AUTOSAR XML (schema 4-0-3)
package /CHMR_Code_pkg/CHMR_Code_swc
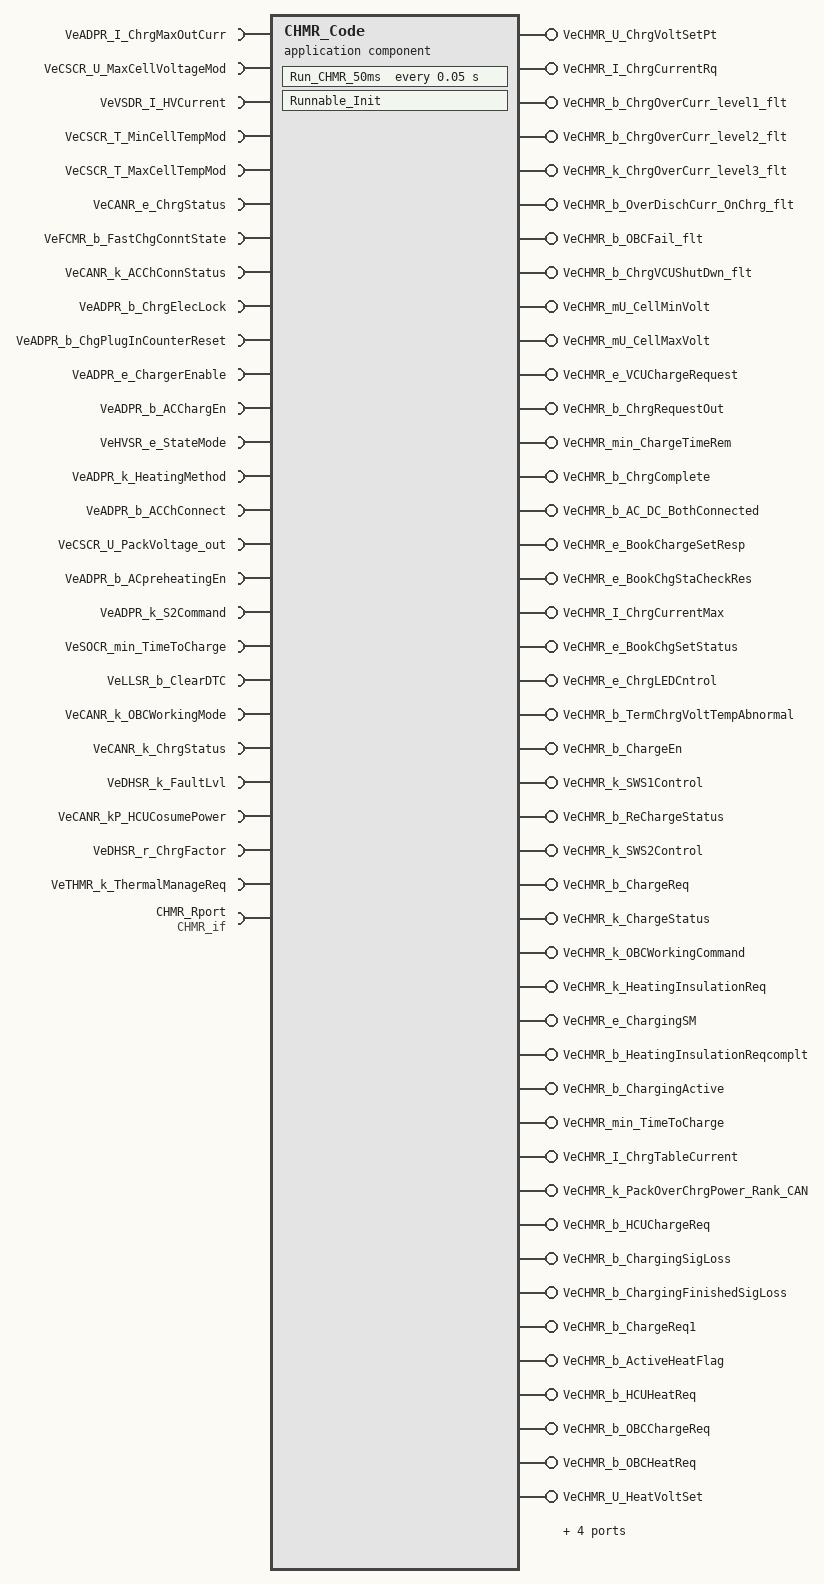
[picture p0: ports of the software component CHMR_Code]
  application sw component type CHMR_Code
    26 x require port:
      VeADPR_I_ChrgMaxOutCurr: nonqueued-receiver-com-spec{data-element=VeADPR_I_ChrgMaxOutCurr, init-value=0}, required-interface=VeADPR_I_ChrgMaxOutCurr
      VeCSCR_U_MaxCellVoltageMod: nonqueued-receiver-com-spec{data-element=VeCSCR_U_MaxCellVoltageMod, init-value=0}, required-interface=VeCSCR_U_MaxCellVoltageMod
      VeVSDR_I_HVCurrent: nonqueued-receiver-com-spec{data-element=VeVSDR_I_HVCurrent, init-value=0}, required-interface=VeVSDR_I_HVCurrent
      VeCSCR_T_MinCellTempMod: nonqueued-receiver-com-spec{data-element=VeCSCR_T_MinCellTempMod, init-value=0}, required-interface=VeCSCR_T_MinCellTempMod
      VeCSCR_T_MaxCellTempMod: nonqueued-receiver-com-spec{data-element=VeCSCR_T_MaxCellTempMod, init-value=0}, required-interface=VeCSCR_T_MaxCellTempMod
      VeCANR_e_ChrgStatus: nonqueued-receiver-com-spec{data-element=VeCANR_e_ChrgStatus, init-value=CeCHMR_e_ChrgModeReserved1}, required-interface=VeCANR_e_ChrgStatus
      VeFCMR_b_FastChgConntState: nonqueued-receiver-com-spec{data-element=VeFCMR_b_FastChgConntState, init-value=0}, required-interface=VeFCMR_b_FastChgConntState
      VeCANR_k_ACChConnStatus: nonqueued-receiver-com-spec{data-element=VeCANR_k_ACChConnStatus, init-value=0}, required-interface=VeCANR_k_ACChConnStatus
      VeADPR_b_ChrgElecLock: nonqueued-receiver-com-spec{data-element=VeADPR_b_ChrgElecLock, init-value=0}, required-interface=VeADPR_b_ChrgElecLock
      VeADPR_b_ChgPlugInCounterReset: nonqueued-receiver-com-spec{data-element=VeADPR_b_ChgPlugInCounterReset, init-value=0}, required-interface=VeADPR_b_ChgPlugInCounterReset
      VeADPR_e_ChargerEnable: nonqueued-receiver-com-spec{data-element=VeADPR_e_ChargerEnable, init-value=CeCHMR_e_OBC_ChrgEnblDefault}, required-interface=VeADPR_e_ChargerEnable
      VeADPR_b_ACChargEn: nonqueued-receiver-com-spec{data-element=VeADPR_b_ACChargEn, init-value=0}, required-interface=VeADPR_b_ACChargEn
      VeHVSR_e_StateMode: nonqueued-receiver-com-spec{data-element=VeHVSR_e_StateMode, init-value=CeHVSR_e_StateModeReserved}, required-interface=VeHVSR_e_StateMode
      VeADPR_k_HeatingMethod: nonqueued-receiver-com-spec{data-element=VeADPR_k_HeatingMethod, init-value=0}, required-interface=VeADPR_k_HeatingMethod
      VeADPR_b_ACChConnect: nonqueued-receiver-com-spec{data-element=VeADPR_b_ACChConnect, init-value=0}, required-interface=VeADPR_b_ACChConnect
      VeCSCR_U_PackVoltage_out: nonqueued-receiver-com-spec{data-element=VeCSCR_U_PackVoltage_out, init-value=0}, required-interface=VeCSCR_U_PackVoltage_out
      VeADPR_b_ACpreheatingEn: nonqueued-receiver-com-spec{data-element=VeADPR_b_ACpreheatingEn, init-value=0}, required-interface=VeADPR_b_ACpreheatingEn
      VeADPR_k_S2Command: nonqueued-receiver-com-spec{data-element=VeADPR_k_S2Command, init-value=0}, required-interface=VeADPR_k_S2Command
      VeSOCR_min_TimeToCharge: nonqueued-receiver-com-spec{data-element=VeSOCR_min_TimeToCharge, init-value=0}, required-interface=VeSOCR_min_TimeToCharge
      VeLLSR_b_ClearDTC: nonqueued-receiver-com-spec{data-element=VeLLSR_b_ClearDTC, init-value=0}, required-interface=VeLLSR_b_ClearDTC
      VeCANR_k_OBCWorkingMode: nonqueued-receiver-com-spec{data-element=VeCANR_k_OBCWorkingMode, init-value=0}, required-interface=VeCANR_k_OBCWorkingMode
      VeCANR_k_ChrgStatus: nonqueued-receiver-com-spec{data-element=VeCANR_k_ChrgStatus, init-value=0}, required-interface=VeCANR_k_ChrgStatus
      VeDHSR_k_FaultLvl: nonqueued-receiver-com-spec{data-element=VeDHSR_k_FaultLvl, init-value=0}, required-interface=VeDHSR_k_FaultLvl
      VeCANR_kP_HCUCosumePower: nonqueued-receiver-com-spec{data-element=VeCANR_kP_HCUCosumePower, init-value=0}, required-interface=VeCANR_kP_HCUCosumePower
      VeDHSR_r_ChrgFactor: nonqueued-receiver-com-spec{data-element=VeDHSR_r_ChrgFactor, init-value=0}, required-interface=VeDHSR_r_ChrgFactor
      VeTHMR_k_ThermalManageReq: nonqueued-receiver-com-spec{data-element=VeTHMR_k_ThermalManageReq, init-value=0}, required-interface=VeTHMR_k_ThermalManageReq
    48 x provide port:
      VeCHMR_U_ChrgVoltSetPt: nonqueued-sender-com-spec{data-element=VeCHMR_U_ChrgVoltSetPt, init-value=0}, provided-interface=VeCHMR_U_ChrgVoltSetPt
      VeCHMR_I_ChrgCurrentRq: nonqueued-sender-com-spec{data-element=VeCHMR_I_ChrgCurrentRq, init-value=0}, provided-interface=VeCHMR_I_ChrgCurrentRq
      VeCHMR_b_ChrgOverCurr_level1_flt: nonqueued-sender-com-spec{data-element=VeCHMR_b_ChrgOverCurr_level1_flt, init-value=0}, provided-interface=VeCHMR_b_ChrgOverCurr_level1_flt
      VeCHMR_b_ChrgOverCurr_level2_flt: nonqueued-sender-com-spec{data-element=VeCHMR_b_ChrgOverCurr_level2_flt, init-value=0}, provided-interface=VeCHMR_b_ChrgOverCurr_level2_flt
      VeCHMR_k_ChrgOverCurr_level3_flt: nonqueued-sender-com-spec{data-element=VeCHMR_k_ChrgOverCurr_level3_flt, init-value=0}, provided-interface=VeCHMR_k_ChrgOverCurr_level3_flt
      VeCHMR_b_OverDischCurr_OnChrg_flt: nonqueued-sender-com-spec{data-element=VeCHMR_b_OverDischCurr_OnChrg_flt, init-value=0}, provided-interface=VeCHMR_b_OverDischCurr_OnChrg_flt
      VeCHMR_b_OBCFail_flt: nonqueued-sender-com-spec{data-element=VeCHMR_b_OBCFail_flt, init-value=0}, provided-interface=VeCHMR_b_OBCFail_flt
      VeCHMR_b_ChrgVCUShutDwn_flt: nonqueued-sender-com-spec{data-element=VeCHMR_b_ChrgVCUShutDwn_flt, init-value=0}, provided-interface=VeCHMR_b_ChrgVCUShutDwn_flt
      VeCHMR_mU_CellMinVolt: nonqueued-sender-com-spec{data-element=VeCHMR_mU_CellMinVolt, init-value=0}, provided-interface=VeCHMR_mU_CellMinVolt
      VeCHMR_mU_CellMaxVolt: nonqueued-sender-com-spec{data-element=VeCHMR_mU_CellMaxVolt, init-value=0}, provided-interface=VeCHMR_mU_CellMaxVolt
      VeCHMR_e_VCUChargeRequest: nonqueued-sender-com-spec{data-element=VeCHMR_e_VCUChargeRequest, init-value=CeCHMR_e_VCU_ChargeRequestDflt}, provided-interface=VeCHMR_e_VCUChargeRequest
      VeCHMR_b_ChrgRequestOut: nonqueued-sender-com-spec{data-element=VeCHMR_b_ChrgRequestOut, init-value=0}, provided-interface=VeCHMR_b_ChrgRequestOut
      VeCHMR_min_ChargeTimeRem: nonqueued-sender-com-spec{data-element=VeCHMR_min_ChargeTimeRem, init-value=0}, provided-interface=VeCHMR_min_ChargeTimeRem
      VeCHMR_b_ChrgComplete: nonqueued-sender-com-spec{data-element=VeCHMR_b_ChrgComplete, init-value=0}, provided-interface=VeCHMR_b_ChrgComplete
      VeCHMR_b_AC_DC_BothConnected: nonqueued-sender-com-spec{data-element=VeCHMR_b_AC_DC_BothConnected, init-value=0}, provided-interface=VeCHMR_b_AC_DC_BothConnected
      VeCHMR_e_BookChargeSetResp: nonqueued-sender-com-spec{data-element=VeCHMR_e_BookChargeSetResp, init-value=CeCHMR_e_BookChargeDflt}, provided-interface=VeCHMR_e_BookChargeSetResp
      VeCHMR_e_BookChgStaCheckRes: nonqueued-sender-com-spec{data-element=VeCHMR_e_BookChgStaCheckRes, init-value=CeCHMR_e_NoAppointmentMade}, provided-interface=VeCHMR_e_BookChgStaCheckRes
      VeCHMR_I_ChrgCurrentMax: nonqueued-sender-com-spec{data-element=VeCHMR_I_ChrgCurrentMax, init-value=0}, provided-interface=VeCHMR_I_ChrgCurrentMax
      VeCHMR_e_BookChgSetStatus: nonqueued-sender-com-spec{data-element=VeCHMR_e_BookChgSetStatus, init-value=CeCHMR_e_BookChargeDflt}, provided-interface=VeCHMR_e_BookChgSetStatus
      VeCHMR_e_ChrgLEDCntrol: nonqueued-sender-com-spec{data-element=VeCHMR_e_ChrgLEDCntrol, init-value=CeCHMR_e_OBC_ChrgLEDCntroDflt}, provided-interface=VeCHMR_e_ChrgLEDCntrol
      VeCHMR_b_TermChrgVoltTempAbnormal: nonqueued-sender-com-spec{data-element=VeCHMR_b_TermChrgVoltTempAbnormal, init-value=0}, provided-interface=VeCHMR_b_TermChrgVoltTempAbnormal
      VeCHMR_b_ChargeEn: nonqueued-sender-com-spec{data-element=VeCHMR_b_ChargeEn, init-value=0}, provided-interface=VeCHMR_b_ChargeEn
      VeCHMR_k_SWS1Control: nonqueued-sender-com-spec{data-element=VeCHMR_k_SWS1Control, init-value=0}, provided-interface=VeCHMR_k_SWS1Control
      VeCHMR_b_ReChargeStatus: nonqueued-sender-com-spec{data-element=VeCHMR_b_ReChargeStatus, init-value=0}, provided-interface=VeCHMR_b_ReChargeStatus
      VeCHMR_k_SWS2Control: nonqueued-sender-com-spec{data-element=VeCHMR_k_SWS2Control, init-value=0}, provided-interface=VeCHMR_k_SWS2Control
      VeCHMR_b_ChargeReq: nonqueued-sender-com-spec{data-element=VeCHMR_b_ChargeReq, init-value=0}, provided-interface=VeCHMR_b_ChargeReq
      VeCHMR_k_ChargeStatus: nonqueued-sender-com-spec{data-element=VeCHMR_k_ChargeStatus, init-value=0}, provided-interface=VeCHMR_k_ChargeStatus
      VeCHMR_k_OBCWorkingCommand: nonqueued-sender-com-spec{data-element=VeCHMR_k_OBCWorkingCommand, init-value=0}, provided-interface=VeCHMR_k_OBCWorkingCommand
      VeCHMR_k_HeatingInsulationReq: nonqueued-sender-com-spec{data-element=VeCHMR_k_HeatingInsulationReq, init-value=0}, provided-interface=VeCHMR_k_HeatingInsulationReq
      VeCHMR_e_ChargingSM: nonqueued-sender-com-spec{data-element=VeCHMR_e_ChargingSM, init-value=CeCHMR_e_ChargingSM_Off}, provided-interface=VeCHMR_e_ChargingSM
      VeCHMR_b_HeatingInsulationReqcomplt: nonqueued-sender-com-spec{data-element=VeCHMR_b_HeatingInsulationReqcomplt, init-value=0}, provided-interface=VeCHMR_b_HeatingInsulationReqcomplt
      VeCHMR_b_ChargingActive: nonqueued-sender-com-spec{data-element=VeCHMR_b_ChargingActive, init-value=0}, provided-interface=VeCHMR_b_ChargingActive
      VeCHMR_min_TimeToCharge: nonqueued-sender-com-spec{data-element=VeCHMR_min_TimeToCharge, init-value=0}, provided-interface=VeCHMR_min_TimeToCharge
      VeCHMR_I_ChrgTableCurrent: nonqueued-sender-com-spec{data-element=VeCHMR_I_ChrgTableCurrent, init-value=0}, provided-interface=VeCHMR_I_ChrgTableCurrent
      VeCHMR_k_PackOverChrgPower_Rank_CAN: nonqueued-sender-com-spec{data-element=VeCHMR_k_PackOverChrgPower_Rank_CAN, init-value=0}, provided-interface=VeCHMR_k_PackOverChrgPower_Rank_CAN
      VeCHMR_b_HCUChargeReq: nonqueued-sender-com-spec{data-element=VeCHMR_b_HCUChargeReq, init-value=0}, provided-interface=VeCHMR_b_HCUChargeReq
      VeCHMR_b_ChargingSigLoss: nonqueued-sender-com-spec{data-element=VeCHMR_b_ChargingSigLoss, init-value=0}, provided-interface=VeCHMR_b_ChargingSigLoss
      VeCHMR_b_ChargingFinishedSigLoss: nonqueued-sender-com-spec{data-element=VeCHMR_b_ChargingFinishedSigLoss, init-value=0}, provided-interface=VeCHMR_b_ChargingFinishedSigLoss
      VeCHMR_b_ChargeReq1: nonqueued-sender-com-spec{data-element=VeCHMR_b_ChargeReq1, init-value=0}, provided-interface=VeCHMR_b_ChargeReq1
      VeCHMR_b_ActiveHeatFlag: nonqueued-sender-com-spec{data-element=VeCHMR_b_ActiveHeatFlag, init-value=0}, provided-interface=VeCHMR_b_ActiveHeatFlag
      VeCHMR_b_HCUHeatReq: nonqueued-sender-com-spec{data-element=VeCHMR_b_HCUHeatReq, init-value=0}, provided-interface=VeCHMR_b_HCUHeatReq
      VeCHMR_b_OBCChargeReq: nonqueued-sender-com-spec{data-element=VeCHMR_b_OBCChargeReq, init-value=0}, provided-interface=VeCHMR_b_OBCChargeReq
      VeCHMR_b_OBCHeatReq: nonqueued-sender-com-spec{data-element=VeCHMR_b_OBCHeatReq, init-value=0}, provided-interface=VeCHMR_b_OBCHeatReq
      VeCHMR_U_HeatVoltSet: nonqueued-sender-com-spec{data-element=VeCHMR_U_HeatVoltSet, init-value=0}, provided-interface=VeCHMR_U_HeatVoltSet
      VeCHMR_k_PackOverChrgPower_Rank_CAN_CA: nonqueued-sender-com-spec{data-element=VeCHMR_k_PackOverChrgPower_Rank_CAN_CA, init-value=0}, provided-interface=VeCHMR_k_PackOverChrgPower_Rank_CAN_CA
      VeCHMR_b_HeatReset: nonqueued-sender-com-spec{data-element=VeCHMR_b_HeatReset, init-value=0}, provided-interface=VeCHMR_b_HeatReset
      VeCHMR_b_HCUReq: nonqueued-sender-com-spec{data-element=VeCHMR_b_HCUReq, init-value=0}, provided-interface=VeCHMR_b_HCUReq
      VeCHMR_k_PackChargingThermalSt: nonqueued-sender-com-spec{data-element=VeCHMR_k_PackChargingThermalSt, init-value=0}, provided-interface=VeCHMR_k_PackChargingThermalSt
    require port CHMR_Rport: required-interface=CHMR_if
    behavior CHMR_Code: data-type-mapping=CHMR_CodeDataTypeMappingsSet, handle-termination-and-restart=NO-SUPPORT
      constant-memorys:
        parameter data prototype CtCHMR_I_MaxChrgCurrent: category=COM_AXIS, sw-calibration-access=READ-WRITE, type=Appl_CtCHMR_I_MaxChrgCurrent, init-value=constant-reference={short-label=CtCHMR_I_MaxChrgCurrent, constant=CtCHMR_I_MaxChrgCurrent}
        parameter data prototype CxCHMR_I_MaxChrgCurrent: category=COM_AXIS, sw-calibration-access=READ-WRITE, type=Appl_CxCHMR_I_MaxChrgCurrent, init-value=constant-reference={short-label=CxCHMR_I_MaxChrgCurrent, constant=CxCHMR_I_MaxChrgCurrent}
        parameter data prototype CzCHMR_I_MaxChrgCurrent_data: category=MAP, sw-calibration-access=READ-WRITE, type=Appl_CzCHMR_I_MaxChrgCurrent_data, init-value=constant-reference={short-label=CzCHMR_I_MaxChrgCurrent_data, constant=CzCHMR_I_MaxChrgCurrent_data}
      static-memorys:
        data VeCHMR_t_ChargingSM_Timer: category=VALUE, sw-calibration-access=READ-ONLY, type=Float
        data VeCHMR_e_ChrgFltSts: category=VALUE, sw-calibration-access=READ-ONLY, type=TeCHMR_e_ChrgOnbrdFailStatus
      timing event Event_Run_CHMR_50ms: start-on-event=Run_CHMR_50ms, period=0.05
      runnable Runnable_Init: symbol=CHMR_Code_Init
        data-send-points:
          24 x access:
            OUT_VeCHMR_b_ChrgOverCurr_level1_flt_VeCHMR_b_ef3dc60b3fd9fb9b: accessed-variable=VeCHMR_b_ChrgOverCurr_level1_flt.VeCHMR_b_ChrgOverCurr_level1_flt
            OUT_VeCHMR_b_ChrgOverCurr_level2_flt_VeCHMR_b_e2b40647eb9cefd6: accessed-variable=VeCHMR_b_ChrgOverCurr_level2_flt.VeCHMR_b_ChrgOverCurr_level2_flt
            OUT_VeCHMR_b_TermChrgVoltTempAbnormal_VeCHMR_a2864ede080a60cd: accessed-variable=VeCHMR_b_TermChrgVoltTempAbnormal.VeCHMR_b_TermChrgVoltTempAbnormal
            OUT_VeCHMR_e_ChrgLEDCntrol_VeCHMR_e_ChrgLEDCntrol: accessed-variable=VeCHMR_e_ChrgLEDCntrol.VeCHMR_e_ChrgLEDCntrol
            OUT_VeCHMR_mU_CellMinVolt_VeCHMR_mU_CellMinVolt: accessed-variable=VeCHMR_mU_CellMinVolt.VeCHMR_mU_CellMinVolt
            OUT_VeCHMR_mU_CellMaxVolt_VeCHMR_mU_CellMaxVolt: accessed-variable=VeCHMR_mU_CellMaxVolt.VeCHMR_mU_CellMaxVolt
            OUT_VeCHMR_e_VCUChargeRequest_VeCHMR_e_VCUChargeRequest: accessed-variable=VeCHMR_e_VCUChargeRequest.VeCHMR_e_VCUChargeRequest
            OUT_VeCHMR_b_ChrgRequestOut_VeCHMR_b_ChrgRequestOut: accessed-variable=VeCHMR_b_ChrgRequestOut.VeCHMR_b_ChrgRequestOut
            OUT_VeCHMR_min_ChargeTimeRem_VeCHMR_min_ChargeTimeRem: accessed-variable=VeCHMR_min_ChargeTimeRem.VeCHMR_min_ChargeTimeRem
            OUT_VeCHMR_e_BookChargeSetResp_VeCHMR_e_BookChargeSetResp: accessed-variable=VeCHMR_e_BookChargeSetResp.VeCHMR_e_BookChargeSetResp
            OUT_VeCHMR_e_BookChgSetStatus_VeCHMR_e_BookChgSetStatus: accessed-variable=VeCHMR_e_BookChgSetStatus.VeCHMR_e_BookChgSetStatus
            OUT_VeCHMR_e_BookChgStaCheckRes_VeCHMR_e_BookChgStaCheckRes: accessed-variable=VeCHMR_e_BookChgStaCheckRes.VeCHMR_e_BookChgStaCheckRes
            OUT_VeCHMR_b_OverDischCurr_OnChrg_flt_VeCHMR_34006cf33559e537: accessed-variable=VeCHMR_b_OverDischCurr_OnChrg_flt.VeCHMR_b_OverDischCurr_OnChrg_flt
            OUT_VeCHMR_k_SWS1Control_VeCHMR_k_SWS1Control: accessed-variable=VeCHMR_k_SWS1Control.VeCHMR_k_SWS1Control
            OUT_VeCHMR_k_OBCWorkingCommand_VeCHMR_k_OBCWorkingCommand: accessed-variable=VeCHMR_k_OBCWorkingCommand.VeCHMR_k_OBCWorkingCommand
            OUT_VeCHMR_e_ChargingSM_VeCHMR_e_ChargingSM: accessed-variable=VeCHMR_e_ChargingSM.VeCHMR_e_ChargingSM
            OUT_VeCHMR_b_ChargingActive_VeCHMR_b_ChargingActive: accessed-variable=VeCHMR_b_ChargingActive.VeCHMR_b_ChargingActive
            OUT_VeCHMR_k_PackOverChrgPower_Rank_CAN_VeCHM_e06598267a1a87d6: accessed-variable=VeCHMR_k_PackOverChrgPower_Rank_CAN.VeCHMR_k_PackOverChrgPower_Rank_CAN
            OUT_VeCHMR_b_ChargingSigLoss_VeCHMR_b_ChargingSigLoss: accessed-variable=VeCHMR_b_ChargingSigLoss.VeCHMR_b_ChargingSigLoss
            OUT_VeCHMR_b_ChargingFinishedSigLoss_VeCHMR_b_994479137778fb77: accessed-variable=VeCHMR_b_ChargingFinishedSigLoss.VeCHMR_b_ChargingFinishedSigLoss
            OUT_VeCHMR_b_ChargeReq1_VeCHMR_b_ChargeReq1: accessed-variable=VeCHMR_b_ChargeReq1.VeCHMR_b_ChargeReq1
            OUT_VeCHMR_b_OBCHeatReq_VeCHMR_b_OBCHeatReq: accessed-variable=VeCHMR_b_OBCHeatReq.VeCHMR_b_OBCHeatReq
            OUT_VeCHMR_b_HeatReset_VeCHMR_b_HeatReset: accessed-variable=VeCHMR_b_HeatReset.VeCHMR_b_HeatReset
            OUT_VeCHMR_b_HCUReq_VeCHMR_b_HCUReq: accessed-variable=VeCHMR_b_HCUReq.VeCHMR_b_HCUReq
        parameter access CALPRM_CHMR_Rport_KeCHMR_mU_CellMaxVoltOvrd: accessed-parameter=CHMR_Rport.KeCHMR_mU_CellMaxVoltOvrd
        parameter access CALPRM_CHMR_Rport_KeCHMR_mU_CellMinVoltOvrd: accessed-parameter=CHMR_Rport.KeCHMR_mU_CellMinVoltOvrd
        parameter access CALPRM_CHMR_Rport_KeCHMR_min_ChargeTimeRemOvrd: accessed-parameter=CHMR_Rport.KeCHMR_min_ChargeTimeRemOvrd
      runnable Run_CHMR_50ms
        data-read-access:
          26 x access:
            IN_VeADPR_I_ChrgMaxOutCurr_VeADPR_I_ChrgMaxOutCurr: accessed-variable=VeADPR_I_ChrgMaxOutCurr.VeADPR_I_ChrgMaxOutCurr
            IN_VeADPR_b_ACChConnect_VeADPR_b_ACChConnect: accessed-variable=VeADPR_b_ACChConnect.VeADPR_b_ACChConnect
            IN_VeADPR_b_ACChargEn_VeADPR_b_ACChargEn: accessed-variable=VeADPR_b_ACChargEn.VeADPR_b_ACChargEn
            IN_VeADPR_b_ACpreheatingEn_VeADPR_b_ACpreheatingEn: accessed-variable=VeADPR_b_ACpreheatingEn.VeADPR_b_ACpreheatingEn
            IN_VeADPR_b_ChgPlugInCounterReset_VeADPR_b_Ch_465b256f1c723605: accessed-variable=VeADPR_b_ChgPlugInCounterReset.VeADPR_b_ChgPlugInCounterReset
            IN_VeADPR_b_ChrgElecLock_VeADPR_b_ChrgElecLock: accessed-variable=VeADPR_b_ChrgElecLock.VeADPR_b_ChrgElecLock
            IN_VeADPR_e_ChargerEnable_VeADPR_e_ChargerEnable: accessed-variable=VeADPR_e_ChargerEnable.VeADPR_e_ChargerEnable
            IN_VeADPR_k_HeatingMethod_VeADPR_k_HeatingMethod: accessed-variable=VeADPR_k_HeatingMethod.VeADPR_k_HeatingMethod
            IN_VeADPR_k_S2Command_VeADPR_k_S2Command: accessed-variable=VeADPR_k_S2Command.VeADPR_k_S2Command
            IN_VeCANR_e_ChrgStatus_VeCANR_e_ChrgStatus: accessed-variable=VeCANR_e_ChrgStatus.VeCANR_e_ChrgStatus
            IN_VeCANR_kP_HCUCosumePower_VeCANR_kP_HCUCosumePower: accessed-variable=VeCANR_kP_HCUCosumePower.VeCANR_kP_HCUCosumePower
            IN_VeCANR_k_ACChConnStatus_VeCANR_k_ACChConnStatus: accessed-variable=VeCANR_k_ACChConnStatus.VeCANR_k_ACChConnStatus
            IN_VeCANR_k_ChrgStatus_VeCANR_k_ChrgStatus: accessed-variable=VeCANR_k_ChrgStatus.VeCANR_k_ChrgStatus
            IN_VeCANR_k_OBCWorkingMode_VeCANR_k_OBCWorkingMode: accessed-variable=VeCANR_k_OBCWorkingMode.VeCANR_k_OBCWorkingMode
            IN_VeCSCR_T_MaxCellTempMod_VeCSCR_T_MaxCellTempMod: accessed-variable=VeCSCR_T_MaxCellTempMod.VeCSCR_T_MaxCellTempMod
            IN_VeCSCR_T_MinCellTempMod_VeCSCR_T_MinCellTempMod: accessed-variable=VeCSCR_T_MinCellTempMod.VeCSCR_T_MinCellTempMod
            IN_VeCSCR_U_MaxCellVoltageMod_VeCSCR_U_MaxCellVoltageMod: accessed-variable=VeCSCR_U_MaxCellVoltageMod.VeCSCR_U_MaxCellVoltageMod
            IN_VeCSCR_U_PackVoltage_out_VeCSCR_U_PackVoltage_out: accessed-variable=VeCSCR_U_PackVoltage_out.VeCSCR_U_PackVoltage_out
            IN_VeDHSR_k_FaultLvl_VeDHSR_k_FaultLvl: accessed-variable=VeDHSR_k_FaultLvl.VeDHSR_k_FaultLvl
            IN_VeDHSR_r_ChrgFactor_VeDHSR_r_ChrgFactor: accessed-variable=VeDHSR_r_ChrgFactor.VeDHSR_r_ChrgFactor
            IN_VeFCMR_b_FastChgConntState_VeFCMR_b_FastChgConntState: accessed-variable=VeFCMR_b_FastChgConntState.VeFCMR_b_FastChgConntState
            IN_VeHVSR_e_StateMode_VeHVSR_e_StateMode: accessed-variable=VeHVSR_e_StateMode.VeHVSR_e_StateMode
            IN_VeLLSR_b_ClearDTC_VeLLSR_b_ClearDTC: accessed-variable=VeLLSR_b_ClearDTC.VeLLSR_b_ClearDTC
            IN_VeSOCR_min_TimeToCharge_VeSOCR_min_TimeToCharge: accessed-variable=VeSOCR_min_TimeToCharge.VeSOCR_min_TimeToCharge
            IN_VeTHMR_k_ThermalManageReq_VeTHMR_k_ThermalManageReq: accessed-variable=VeTHMR_k_ThermalManageReq.VeTHMR_k_ThermalManageReq
            IN_VeVSDR_I_HVCurrent_VeVSDR_I_HVCurrent: accessed-variable=VeVSDR_I_HVCurrent.VeVSDR_I_HVCurrent
        data-send-points:
          48 x access:
            OUT_VeCHMR_b_ChrgOverCurr_level1_flt_VeCHMR_b_ef3dc60b3fd9fb9b: accessed-variable=VeCHMR_b_ChrgOverCurr_level1_flt.VeCHMR_b_ChrgOverCurr_level1_flt
            OUT_VeCHMR_b_ChrgOverCurr_level2_flt_VeCHMR_b_e2b40647eb9cefd6: accessed-variable=VeCHMR_b_ChrgOverCurr_level2_flt.VeCHMR_b_ChrgOverCurr_level2_flt
            OUT_VeCHMR_k_ChrgOverCurr_level3_flt_VeCHMR_k_6d88a7ce90e8a77a: accessed-variable=VeCHMR_k_ChrgOverCurr_level3_flt.VeCHMR_k_ChrgOverCurr_level3_flt
            OUT_VeCHMR_b_OverDischCurr_OnChrg_flt_VeCHMR_34006cf33559e537: accessed-variable=VeCHMR_b_OverDischCurr_OnChrg_flt.VeCHMR_b_OverDischCurr_OnChrg_flt
            OUT_VeCHMR_b_OBCFail_flt_VeCHMR_b_OBCFail_flt: accessed-variable=VeCHMR_b_OBCFail_flt.VeCHMR_b_OBCFail_flt
            OUT_VeCHMR_b_ChrgVCUShutDwn_flt_VeCHMR_b_ChrgVCUShutDwn_flt: accessed-variable=VeCHMR_b_ChrgVCUShutDwn_flt.VeCHMR_b_ChrgVCUShutDwn_flt
            OUT_VeCHMR_mU_CellMinVolt_VeCHMR_mU_CellMinVolt: accessed-variable=VeCHMR_mU_CellMinVolt.VeCHMR_mU_CellMinVolt
            OUT_VeCHMR_mU_CellMaxVolt_VeCHMR_mU_CellMaxVolt: accessed-variable=VeCHMR_mU_CellMaxVolt.VeCHMR_mU_CellMaxVolt
            OUT_VeCHMR_e_VCUChargeRequest_VeCHMR_e_VCUChargeRequest: accessed-variable=VeCHMR_e_VCUChargeRequest.VeCHMR_e_VCUChargeRequest
            OUT_VeCHMR_b_ChrgRequestOut_VeCHMR_b_ChrgRequestOut: accessed-variable=VeCHMR_b_ChrgRequestOut.VeCHMR_b_ChrgRequestOut
            OUT_VeCHMR_min_ChargeTimeRem_VeCHMR_min_ChargeTimeRem: accessed-variable=VeCHMR_min_ChargeTimeRem.VeCHMR_min_ChargeTimeRem
            OUT_VeCHMR_b_ChrgComplete_VeCHMR_b_ChrgComplete: accessed-variable=VeCHMR_b_ChrgComplete.VeCHMR_b_ChrgComplete
            OUT_VeCHMR_b_AC_DC_BothConnected_VeCHMR_b_AC_DC_BothConnected: accessed-variable=VeCHMR_b_AC_DC_BothConnected.VeCHMR_b_AC_DC_BothConnected
            OUT_VeCHMR_e_BookChargeSetResp_VeCHMR_e_BookChargeSetResp: accessed-variable=VeCHMR_e_BookChargeSetResp.VeCHMR_e_BookChargeSetResp
            OUT_VeCHMR_e_BookChgStaCheckRes_VeCHMR_e_BookChgStaCheckRes: accessed-variable=VeCHMR_e_BookChgStaCheckRes.VeCHMR_e_BookChgStaCheckRes
            OUT_VeCHMR_I_ChrgCurrentMax_VeCHMR_I_ChrgCurrentMax: accessed-variable=VeCHMR_I_ChrgCurrentMax.VeCHMR_I_ChrgCurrentMax
            OUT_VeCHMR_e_BookChgSetStatus_VeCHMR_e_BookChgSetStatus: accessed-variable=VeCHMR_e_BookChgSetStatus.VeCHMR_e_BookChgSetStatus
            OUT_VeCHMR_e_ChrgLEDCntrol_VeCHMR_e_ChrgLEDCntrol: accessed-variable=VeCHMR_e_ChrgLEDCntrol.VeCHMR_e_ChrgLEDCntrol
            OUT_VeCHMR_b_TermChrgVoltTempAbnormal_VeCHMR_a2864ede080a60cd: accessed-variable=VeCHMR_b_TermChrgVoltTempAbnormal.VeCHMR_b_TermChrgVoltTempAbnormal
            OUT_VeCHMR_b_ChargeEn_VeCHMR_b_ChargeEn: accessed-variable=VeCHMR_b_ChargeEn.VeCHMR_b_ChargeEn
            OUT_VeCHMR_k_SWS1Control_VeCHMR_k_SWS1Control: accessed-variable=VeCHMR_k_SWS1Control.VeCHMR_k_SWS1Control
            OUT_VeCHMR_b_ReChargeStatus_VeCHMR_b_ReChargeStatus: accessed-variable=VeCHMR_b_ReChargeStatus.VeCHMR_b_ReChargeStatus
            OUT_VeCHMR_I_ChrgCurrentRq_VeCHMR_I_ChrgCurrentRq: accessed-variable=VeCHMR_I_ChrgCurrentRq.VeCHMR_I_ChrgCurrentRq
            OUT_VeCHMR_U_ChrgVoltSetPt_VeCHMR_U_ChrgVoltSetPt: accessed-variable=VeCHMR_U_ChrgVoltSetPt.VeCHMR_U_ChrgVoltSetPt
            OUT_VeCHMR_k_SWS2Control_VeCHMR_k_SWS2Control: accessed-variable=VeCHMR_k_SWS2Control.VeCHMR_k_SWS2Control
            OUT_VeCHMR_b_ChargeReq_VeCHMR_b_ChargeReq: accessed-variable=VeCHMR_b_ChargeReq.VeCHMR_b_ChargeReq
            OUT_VeCHMR_k_ChargeStatus_VeCHMR_k_ChargeStatus: accessed-variable=VeCHMR_k_ChargeStatus.VeCHMR_k_ChargeStatus
            OUT_VeCHMR_k_OBCWorkingCommand_VeCHMR_k_OBCWorkingCommand: accessed-variable=VeCHMR_k_OBCWorkingCommand.VeCHMR_k_OBCWorkingCommand
            OUT_VeCHMR_k_HeatingInsulationReq_VeCHMR_k_He_ff3bbd8265ee0908: accessed-variable=VeCHMR_k_HeatingInsulationReq.VeCHMR_k_HeatingInsulationReq
            OUT_VeCHMR_e_ChargingSM_VeCHMR_e_ChargingSM: accessed-variable=VeCHMR_e_ChargingSM.VeCHMR_e_ChargingSM
            OUT_VeCHMR_b_HeatingInsulationReqcomplt_VeCHM_9af683376cf32940: accessed-variable=VeCHMR_b_HeatingInsulationReqcomplt.VeCHMR_b_HeatingInsulationReqcomplt
            OUT_VeCHMR_b_ChargingActive_VeCHMR_b_ChargingActive: accessed-variable=VeCHMR_b_ChargingActive.VeCHMR_b_ChargingActive
            OUT_VeCHMR_min_TimeToCharge_VeCHMR_min_TimeToCharge: accessed-variable=VeCHMR_min_TimeToCharge.VeCHMR_min_TimeToCharge
            OUT_VeCHMR_I_ChrgTableCurrent_VeCHMR_I_ChrgTableCurrent: accessed-variable=VeCHMR_I_ChrgTableCurrent.VeCHMR_I_ChrgTableCurrent
            OUT_VeCHMR_k_PackOverChrgPower_Rank_CAN_VeCHM_e06598267a1a87d6: accessed-variable=VeCHMR_k_PackOverChrgPower_Rank_CAN.VeCHMR_k_PackOverChrgPower_Rank_CAN
            OUT_VeCHMR_b_HCUChargeReq_VeCHMR_b_HCUChargeReq: accessed-variable=VeCHMR_b_HCUChargeReq.VeCHMR_b_HCUChargeReq
            OUT_VeCHMR_b_ChargingSigLoss_VeCHMR_b_ChargingSigLoss: accessed-variable=VeCHMR_b_ChargingSigLoss.VeCHMR_b_ChargingSigLoss
            OUT_VeCHMR_b_ChargingFinishedSigLoss_VeCHMR_b_994479137778fb77: accessed-variable=VeCHMR_b_ChargingFinishedSigLoss.VeCHMR_b_ChargingFinishedSigLoss
            OUT_VeCHMR_b_ChargeReq1_VeCHMR_b_ChargeReq1: accessed-variable=VeCHMR_b_ChargeReq1.VeCHMR_b_ChargeReq1
            OUT_VeCHMR_b_ActiveHeatFlag_VeCHMR_b_ActiveHeatFlag: accessed-variable=VeCHMR_b_ActiveHeatFlag.VeCHMR_b_ActiveHeatFlag
            OUT_VeCHMR_b_HCUReq_VeCHMR_b_HCUReq: accessed-variable=VeCHMR_b_HCUReq.VeCHMR_b_HCUReq
            OUT_VeCHMR_b_HCUHeatReq_VeCHMR_b_HCUHeatReq: accessed-variable=VeCHMR_b_HCUHeatReq.VeCHMR_b_HCUHeatReq
            OUT_VeCHMR_b_HeatReset_VeCHMR_b_HeatReset: accessed-variable=VeCHMR_b_HeatReset.VeCHMR_b_HeatReset
            OUT_VeCHMR_b_OBCChargeReq_VeCHMR_b_OBCChargeReq: accessed-variable=VeCHMR_b_OBCChargeReq.VeCHMR_b_OBCChargeReq
            OUT_VeCHMR_b_OBCHeatReq_VeCHMR_b_OBCHeatReq: accessed-variable=VeCHMR_b_OBCHeatReq.VeCHMR_b_OBCHeatReq
            OUT_VeCHMR_U_HeatVoltSet_VeCHMR_U_HeatVoltSet: accessed-variable=VeCHMR_U_HeatVoltSet.VeCHMR_U_HeatVoltSet
            OUT_VeCHMR_k_PackOverChrgPower_Rank_CAN_CA_Ve_cc1e6634ca378a52: accessed-variable=VeCHMR_k_PackOverChrgPower_Rank_CAN_CA.VeCHMR_k_PackOverChrgPower_Rank_CAN_CA
            OUT_VeCHMR_k_PackChargingThermalSt_VeCHMR_k_P_db4ced9331da0c66: accessed-variable=VeCHMR_k_PackChargingThermalSt.VeCHMR_k_PackChargingThermalSt
        46 x parameter access:
          CALPRM_CHMR_Rport_KeCHMR_Ah_BattRatedAh: accessed-parameter=CHMR_Rport.KeCHMR_Ah_BattRatedAh
          CALPRM_CHMR_Rport_KeCHMR_I_ChgOverCurrentResetAddVal: accessed-parameter=CHMR_Rport.KeCHMR_I_ChgOverCurrentResetAddVal
          CALPRM_CHMR_Rport_KeCHMR_I_ChgOverCurrentSetAddVal: accessed-parameter=CHMR_Rport.KeCHMR_I_ChgOverCurrentSetAddVal
          CALPRM_CHMR_Rport_KeCHMR_I_ChrgCurrentRqOvrd: accessed-parameter=CHMR_Rport.KeCHMR_I_ChrgCurrentRqOvrd
          CALPRM_CHMR_Rport_KeCHMR_I_MaxCurrentOvrdValue: accessed-parameter=CHMR_Rport.KeCHMR_I_MaxCurrentOvrdValue
          CALPRM_CHMR_Rport_KeCHMR_I_OverDischCurr_OnChrg: accessed-parameter=CHMR_Rport.KeCHMR_I_OverDischCurr_OnChrg
          CALPRM_CHMR_Rport_KeCHMR_I_PreheatingChrgCurrentRq: accessed-parameter=CHMR_Rport.KeCHMR_I_PreheatingChrgCurrentRq
          CALPRM_CHMR_Rport_KeCHMR_U_DfltVoltageRequest: accessed-parameter=CHMR_Rport.KeCHMR_U_DfltVoltageRequest
          CALPRM_CHMR_Rport_KeCHMR_U_MaxVoltageCVPhase: accessed-parameter=CHMR_Rport.KeCHMR_U_MaxVoltageCVPhase
          CALPRM_CHMR_Rport_KeCHMR_U_MaxVoltageChange: accessed-parameter=CHMR_Rport.KeCHMR_U_MaxVoltageChange
          CALPRM_CHMR_Rport_KeCHMR_U_PreheatVoltageReq: accessed-parameter=CHMR_Rport.KeCHMR_U_PreheatVoltageReq
          CALPRM_CHMR_Rport_KeCHMR_b_ACDCBothConEn: accessed-parameter=CHMR_Rport.KeCHMR_b_ACDCBothConEn
          CALPRM_CHMR_Rport_KeCHMR_b_ACDCBothConOvrd: accessed-parameter=CHMR_Rport.KeCHMR_b_ACDCBothConOvrd
          CALPRM_CHMR_Rport_KeCHMR_b_ChargeCompleteEn: accessed-parameter=CHMR_Rport.KeCHMR_b_ChargeCompleteEn
          CALPRM_CHMR_Rport_KeCHMR_b_ChargeCompleteOvrdVal: accessed-parameter=CHMR_Rport.KeCHMR_b_ChargeCompleteOvrdVal
          CALPRM_CHMR_Rport_KeCHMR_b_ChargeEnOvrdEn: accessed-parameter=CHMR_Rport.KeCHMR_b_ChargeEnOvrdEn
          CALPRM_CHMR_Rport_KeCHMR_b_ChargeEnOvrdVal: accessed-parameter=CHMR_Rport.KeCHMR_b_ChargeEnOvrdVal
          CALPRM_CHMR_Rport_KeCHMR_b_ChrgCurrentRqOvrdCtrl: accessed-parameter=CHMR_Rport.KeCHMR_b_ChrgCurrentRqOvrdCtrl
          CALPRM_CHMR_Rport_KeCHMR_b_ChrgEnOvrCtl: accessed-parameter=CHMR_Rport.KeCHMR_b_ChrgEnOvrCtl
          CALPRM_CHMR_Rport_KeCHMR_b_ChrgEnOvrValue: accessed-parameter=CHMR_Rport.KeCHMR_b_ChrgEnOvrValue
          CALPRM_CHMR_Rport_KeCHMR_b_ChrgOverCurr_level3OvrdEn: accessed-parameter=CHMR_Rport.KeCHMR_b_ChrgOverCurr_level3OvrdEn
          CALPRM_CHMR_Rport_KeCHMR_b_ChrgReqOvrCtl: accessed-parameter=CHMR_Rport.KeCHMR_b_ChrgReqOvrCtl
          CALPRM_CHMR_Rport_KeCHMR_b_ChrgReqOvrValue: accessed-parameter=CHMR_Rport.KeCHMR_b_ChrgReqOvrValue
          CALPRM_CHMR_Rport_KeCHMR_b_ChrgStatusOvrCtl: accessed-parameter=CHMR_Rport.KeCHMR_b_ChrgStatusOvrCtl
          CALPRM_CHMR_Rport_KeCHMR_b_HeatingInsulationReqOvrdEn: accessed-parameter=CHMR_Rport.KeCHMR_b_HeatingInsulationReqOvrdEn
          CALPRM_CHMR_Rport_KeCHMR_b_MaxCurrentOvrdCtrl: accessed-parameter=CHMR_Rport.KeCHMR_b_MaxCurrentOvrdCtrl
          CALPRM_CHMR_Rport_KeCHMR_b_OBCFailOvrdEn: accessed-parameter=CHMR_Rport.KeCHMR_b_OBCFailOvrdEn
          CALPRM_CHMR_Rport_KeCHMR_b_OBCFailOvrdVal: accessed-parameter=CHMR_Rport.KeCHMR_b_OBCFailOvrdVal
          CALPRM_CHMR_Rport_KeCHMR_g_ChgOverCurrentResetGain: accessed-parameter=CHMR_Rport.KeCHMR_g_ChgOverCurrentResetGain
          CALPRM_CHMR_Rport_KeCHMR_g_ChgOverCurrentSetGain: accessed-parameter=CHMR_Rport.KeCHMR_g_ChgOverCurrentSetGain
          CALPRM_CHMR_Rport_KeCHMR_k_ChrgOverCurr_level3OvrdVal: accessed-parameter=CHMR_Rport.KeCHMR_k_ChrgOverCurr_level3OvrdVal
          CALPRM_CHMR_Rport_KeCHMR_k_ChrgStatusOvrValue: accessed-parameter=CHMR_Rport.KeCHMR_k_ChrgStatusOvrValue
          CALPRM_CHMR_Rport_KeCHMR_k_HeatingInsulationReqOvrdVal: accessed-parameter=CHMR_Rport.KeCHMR_k_HeatingInsulationReqOvrdVal
          CALPRM_CHMR_Rport_KeCHMR_mU_CellMaxVoltOvrd: accessed-parameter=CHMR_Rport.KeCHMR_mU_CellMaxVoltOvrd
          CALPRM_CHMR_Rport_KeCHMR_mU_CellMinVoltOvrd: accessed-parameter=CHMR_Rport.KeCHMR_mU_CellMinVoltOvrd
          CALPRM_CHMR_Rport_KeCHMR_min_ChargeTimeRemOvrd: accessed-parameter=CHMR_Rport.KeCHMR_min_ChargeTimeRemOvrd
          CALPRM_CHMR_Rport_KeCHMR_t_CHMR_FunctionCallRate: accessed-parameter=CHMR_Rport.KeCHMR_t_CHMR_FunctionCallRate
          CALPRM_CHMR_Rport_KeCHMR_t_ChrgEnDelay1: accessed-parameter=CHMR_Rport.KeCHMR_t_ChrgEnDelay1
          CALPRM_CHMR_Rport_KeCHMR_t_FunctionCallRate: accessed-parameter=CHMR_Rport.KeCHMR_t_FunctionCallRate
          CALPRM_CHMR_Rport_KeCHMR_t_MinTimeInterrupt2Shutdown: accessed-parameter=CHMR_Rport.KeCHMR_t_MinTimeInterrupt2Shutdown
          CALPRM_CHMR_Rport_KeCHMR_t_MinTimeShDown2OFF: accessed-parameter=CHMR_Rport.KeCHMR_t_MinTimeShDown2OFF
          CALPRM_CHMR_Rport_KeCHMR_t_OverCurrentThrehldResetDelay: accessed-parameter=CHMR_Rport.KeCHMR_t_OverCurrentThrehldResetDelay
          CALPRM_CHMR_Rport_KeCHMR_t_OverCurrentThrehldSetDelay: accessed-parameter=CHMR_Rport.KeCHMR_t_OverCurrentThrehldSetDelay
          CALPRM_CHMR_Rport_KeCHMR_t_SendSWS2command_Timer: accessed-parameter=CHMR_Rport.KeCHMR_t_SendSWS2command_Timer
          CALPRM_CHMR_Rport_KeCHMR_t_TimeChrgNoPerform: accessed-parameter=CHMR_Rport.KeCHMR_t_TimeChrgNoPerform
          CALPRM_CHMR_Rport_KeCHMR_t_TimeOverDischEDuCharg: accessed-parameter=CHMR_Rport.KeCHMR_t_TimeOverDischEDuCharg
package /CalibrationComponents
  parameter sw component type CHMR: data-type-mapping=CHMR_CodeDataTypeMappingsSet
    provide port CHMR_Pport: provided-interface=CHMR_if
      provided-com-specs:
        init-value=55, parameter=KeCHMR_Ah_BattRatedAh
        init-value=0, parameter=KeCHMR_I_ChgOverCurrentResetAddVal
        init-value=2, parameter=KeCHMR_I_ChgOverCurrentSetAddVal
        init-value=1, parameter=KeCHMR_I_ChrgCurrentRqOvrd
        init-value=0, parameter=KeCHMR_I_MaxCurrentOvrdValue
        init-value=30, parameter=KeCHMR_I_OverDischCurr_OnChrg
        init-value=1, parameter=KeCHMR_I_PreheatingChrgCurrentRq
        init-value=401, parameter=KeCHMR_U_DfltVoltageRequest
        init-value=4.179999828338623, parameter=KeCHMR_U_MaxVoltageCVPhase
        init-value=0.019999999552965164, parameter=KeCHMR_U_MaxVoltageChange
        init-value=350, parameter=KeCHMR_U_PreheatVoltageReq
        init-value=1, parameter=KeCHMR_g_ChgOverCurrentResetGain
        init-value=1.100000023841858, parameter=KeCHMR_g_ChgOverCurrentSetGain
        init-value=3650, parameter=KeCHMR_mU_CellMaxVoltOvrd
        init-value=2800, parameter=KeCHMR_mU_CellMinVoltOvrd
        init-value=1, parameter=KeCHMR_min_ChargeTimeRemOvrd
        init-value=0.05000000074505806, parameter=KeCHMR_t_CHMR_FunctionCallRate
        init-value=0.30000001192092896, parameter=KeCHMR_t_ChrgEnDelay1
        init-value=0.05000000074505806, parameter=KeCHMR_t_FunctionCallRate
        init-value=0.019999999552965164, parameter=KeCHMR_t_MinTime2SwitchState{1..6}
        init-value=0.019999999552965164, parameter=KeCHMR_t_MinTime2SwitchState8
        init-value=10, parameter=KeCHMR_t_MinTimeInterrupt2Shutdown
        init-value=10, parameter=KeCHMR_t_MinTimeShDown2OFF
        init-value=3, parameter=KeCHMR_t_OverCurrentThrehldResetDelay
        init-value=3, parameter=KeCHMR_t_OverCurrentThrehldSetDelay
        init-value=0.30000001192092896, parameter=KeCHMR_t_SendSWS2command_Timer
        init-value=300, parameter=KeCHMR_t_TimeChrgNoPerform
        init-value=2, parameter=KeCHMR_t_TimeOverDischEDuCharg
        init-value=2, parameter=KeCHMR_t_WaitVCUAllow
        init-value=0, parameter=KeCHMR_b_ACDCBothConEn
        init-value=0, parameter=KeCHMR_b_ACDCBothConOvrd
        init-value=0, parameter=KeCHMR_b_ChargeCompleteEn
        init-value=0, parameter=KeCHMR_b_ChargeCompleteOvrdVal
        init-value=0, parameter=KeCHMR_b_ChargeEnOvrdEn
        init-value=0, parameter=KeCHMR_b_ChargeEnOvrdVal
        init-value=0, parameter=KeCHMR_b_ChrgCurrentRqOvrdCtrl
        init-value=0, parameter=KeCHMR_b_ChrgEnOvrCtl
        init-value=0, parameter=KeCHMR_b_ChrgEnOvrValue
        init-value=0, parameter=KeCHMR_b_ChrgOverCurr_level3OvrdEn
        init-value=0, parameter=KeCHMR_b_ChrgReqOvrCtl
        init-value=0, parameter=KeCHMR_b_ChrgReqOvrValue
        init-value=0, parameter=KeCHMR_b_ChrgStatusOvrCtl
        init-value=0, parameter=KeCHMR_b_HeatingInsulationReqOvrdEn
        init-value=0, parameter=KeCHMR_b_MaxCurrentOvrdCtrl
        init-value=0, parameter=KeCHMR_b_OBCFailOvrdEn
        init-value=0, parameter=KeCHMR_b_OBCFailOvrdVal
        init-value=0, parameter=KeCHMR_k_ChrgOverCurr_level3OvrdVal
        init-value=0, parameter=KeCHMR_k_ChrgStatusOvrValue
        init-value=0, parameter=KeCHMR_k_HeatingInsulationReqOvrdVal
